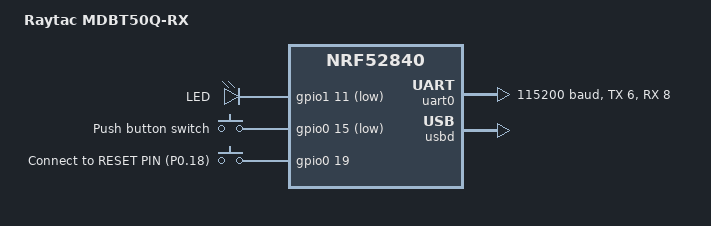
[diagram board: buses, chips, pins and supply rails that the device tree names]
/*
 * Copyright (c) 2017 Linaro Limited
 *
 * SPDX-License-Identifier: Apache-2.0
 */

/dts-v1/;
#include <nordic/nrf52840_qiaa.dtsi>

/ {
	model = "Raytac MDBT50Q-RX";
	compatible = "raytac,mdbt50q-rx";

	chosen {
		zephyr,console = &uart0;
		zephyr,shell-uart = &uart0;
		zephyr,uart-mcumgr = &uart0;
		zephyr,bt-mon-uart = &uart0;
		zephyr,bt-c2h-uart = &uart0;
		zephyr,sram = &sram0;
		zephyr,flash = &flash0;
		zephyr,code-partition = &slot0_partition;
	};

	leds {
		compatible = "gpio-leds";
		led0: led_0 {
			gpios = <&gpio1 11 GPIO_ACTIVE_LOW>;
			label = "LED";
		};
	};

	buttons {
		compatible = "gpio-keys";
		button0: button_0 {
			gpios = <&gpio0 15 (GPIO_PULL_UP | GPIO_ACTIVE_LOW)>;
			label = "Push button switch";
		};
		reset: button_1 {
			gpios = <&gpio0 19 (GPIO_PULL_UP | GPIO_ACTIVE_HIGH)>;
			label = "Connect to RESET PIN (P0.18)";
		};
	};

	/* These aliases are provided for compatibility with samples */
	aliases {
		led0 = &led0;
		sw0 = &button0;
		bootloader-led0 = &led0;
	};
};

&gpio0 {
	status = "okay";
};

&gpio1 {
	status = "okay";
};

&uart0 {
	compatible = "nordic,nrf-uarte";
	status = "okay";
	current-speed = <115200>;
	tx-pin = <6>;
	rx-pin = <8>;
	rts-pin = <5>;
	cts-pin = <7>;
};

&flash0 {

	partitions {
		compatible = "fixed-partitions";
		#address-cells = <1>;
		#size-cells = <1>;

		boot_partition: partition@0 {
			label = "mcuboot";
			reg = <0x00000000 0x00010000>;
		};
		slot0_partition: partition@10000 {
			label = "image-0";
			reg = <0x00010000 0x00067000>;
		};
		slot1_partition: partition@77000 {
			label = "image-1";
			reg = <0x00077000 0x00067000>;
		};
		scratch_partition: partition@de000 {
			label = "image-scratch";
			reg = <0x000de000 0x0001a000>;
		};

		storage_partition: partition@f8000 {
			label = "storage";
			reg = <0x000f8000 0x00005000>;
		};
	};
};

&usbd {
	compatible = "nordic,nrf-usbd";
	status = "okay";
};
